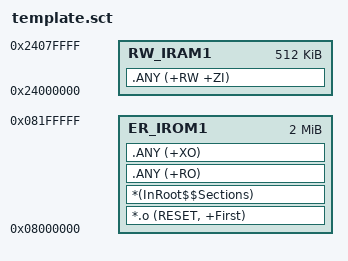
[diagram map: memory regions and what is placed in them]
; *************************************************************
; *** Scatter-Loading Description File generated by uVision ***
; *************************************************************

LR_IROM1 0x08000000 0x00200000  {    ; load region size_region
  ER_IROM1 0x08000000 0x00200000  {  ; load address = execution address
;LR_IROM1 0x08020000 0x001E0000  {    ; load region size_region, +Bootloader Offset
;  ER_IROM1 0x08020000 0x001E0000  {  ; load address = execution address, +Bootloader Offset
   *.o (RESET, +First)
   *(InRoot$$Sections)
   .ANY (+RO)
   .ANY (+XO)
  }
  
  RW_IRAM1 0x24000000 0x00080000  {  ; RW data
   .ANY (+RW +ZI)
  }
  
  ;RW_ITCM 0x00000000 0x00010000  {  ; RW data ITCM
  ; *(.ITCM)
  ;}
  
  ;RW_DTCM 0x20000000 0x00020000  {  ; RW data DTCM
  ; *(.DTCM)
  ;}
  
  ;RW_SRAM12 0x30000000 0x00040000  {  ; RW data SRAM12
  ; *(.SRAM12)
  ;}
  
  ;RW_SRAM4 0x38000000 0x00010000  {  ; RW data SRAM4
  ; *(.SRAM4)
  ;} 
  
  ;EXT_SDRAM 0xc0000000 0x02000000  { ; external SDRAM
  ; *(.ExtSDRAM)
  ;}
}

